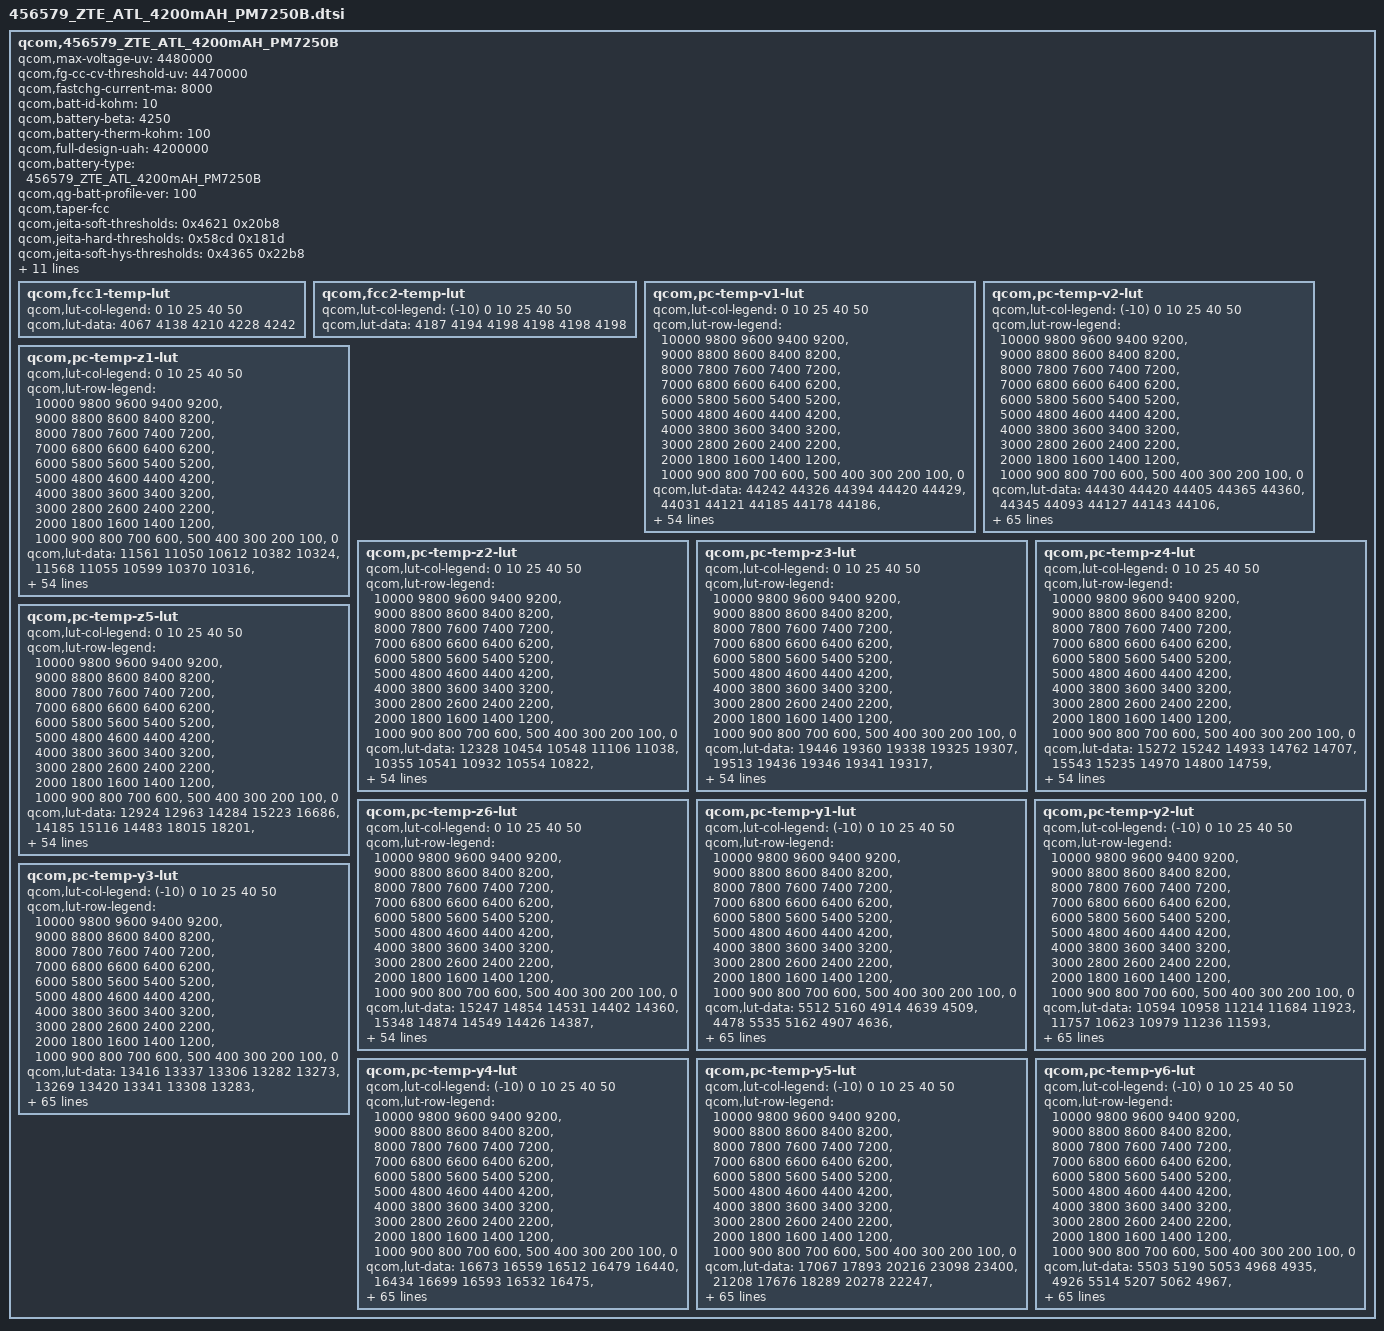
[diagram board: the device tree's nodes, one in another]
qcom,456579_ZTE_ATL_4200mAH_PM7250B {
	/* 456579_ZTE_ATL_4200mAH_PM7250B */
	qcom,max-voltage-uv = <4480000>;
	qcom,fg-cc-cv-threshold-uv = <4470000>;
	qcom,fastchg-current-ma = <8000>;
	qcom,batt-id-kohm = <10>;
	qcom,battery-beta = <4250>;
	qcom,battery-therm-kohm = <100>;
	qcom,full-design-uah = <4200000>;
	qcom,battery-type = "456579_ZTE_ATL_4200mAH_PM7250B";
	qcom,qg-batt-profile-ver = <100>;
	qcom,taper-fcc;
	qcom,jeita-soft-thresholds = <0x4621 0x20b8>;
	qcom,jeita-hard-thresholds = <0x58cd 0x181d>;
	qcom,jeita-soft-hys-thresholds = <0x4365 0x22b8>;
	qcom,jeita-soft-fcc-ua = <4200000 2100000>;
	qcom,jeita-soft-fv-uv = <4450000 4100000>;
	qcom,jeita-cool-step-chg-idx = <1>;
	qcom,jeita-cool-step-chg-fcc = <2100000>;
	qcom,jeita-cool-step-chg-fv = <4200000>;
	qcom,jeita-fcc-ranges = <0  49  800000
				50  149  4200000
				150 389  8000000
				390 409  6000000
				410 429  4800000
				430 449  3000000
				450 549  2000000>;

	qcom,jeita-fv-ranges = <0  49  4450000
				50  149  4450000
				150 389  4480000
				390 409  4480000
				410 429  4480000
				430 449  4480000
				450 549  4100000>;

	qcom,step-chg-ranges = <3400000  4200000  8000000
				4201000  4450000  6000000
				4451000  4480000  2940000>;

	qcom,fcc1-temp-lut {
		qcom,lut-col-legend = <0 10 25 40 50>;
		qcom,lut-data = <4067 4138 4210 4228 4242>;
	};

	qcom,fcc2-temp-lut {
		qcom,lut-col-legend = <(-10) 0 10 25 40 50>;
		qcom,lut-data = <4187 4194 4198 4198 4198 4198>;
	};

	qcom,pc-temp-v1-lut {
		qcom,lut-col-legend = <0 10 25 40 50>;
		qcom,lut-row-legend = <10000 9800 9600 9400 9200>,
			<9000 8800 8600 8400 8200>,
			<8000 7800 7600 7400 7200>,
			<7000 6800 6600 6400 6200>,
			<6000 5800 5600 5400 5200>,
			<5000 4800 4600 4400 4200>,
			<4000 3800 3600 3400 3200>,
			<3000 2800 2600 2400 2200>,
			<2000 1800 1600 1400 1200>,
			<1000 900 800 700 600>,
			<500 400 300 200 100>,
			<0>;

		qcom,lut-data = <44242 44326 44394 44420 44429>,
			<44031 44121 44185 44178 44186>,
			<43819 43915 43974 43968 43972>,
			<43606 43712 43761 43761 43767>,
			<43383 43504 43547 43555 43561>,
			<43149 43281 43328 43346 43355>,
			<42913 43044 43098 43122 43136>,
			<42675 42804 42860 42885 42903>,
			<42437 42564 42620 42646 42667>,
			<42203 42322 42375 42404 42426>,
			<41973 42084 42130 42162 42184>,
			<41746 41846 41891 41923 41944>,
			<41524 41616 41654 41685 41707>,
			<41305 41390 41423 41452 41474>,
			<41097 41172 41197 41225 41247>,
			<40904 40963 40978 41005 41027>,
			<40717 40763 40768 40792 40812>,
			<40522 40567 40564 40587 40604>,
			<40323 40384 40374 40391 40405>,
			<40126 40200 40200 40212 40223>,
			<39940 39985 40016 40029 40040>,
			<39754 39716 39783 39809 39824>,
			<39549 39468 39527 39565 39582>,
			<39298 39288 39317 39349 39364>,
			<39087 39136 39142 39156 39173>,
			<38975 39002 38989 38989 39005>,
			<38896 38883 38857 38856 38865>,
			<38816 38775 38740 38743 38746>,
			<38727 38675 38634 38637 38635>,
			<38639 38581 38537 38535 38531>,
			<38563 38498 38450 38441 38434>,
			<38493 38422 38372 38355 38346>,
			<38431 38355 38301 38276 38265>,
			<38375 38295 38236 38204 38189>,
			<38325 38243 38178 38142 38123>,
			<38282 38194 38124 38080 38055>,
			<38247 38155 38074 38015 37976>,
			<38205 38112 38026 37946 37889>,
			<38130 38044 37958 37866 37797>,
			<38024 37944 37864 37771 37701>,
			<37907 37830 37755 37663 37594>,
			<37772 37699 37631 37537 37465>,
			<37618 37551 37489 37395 37318>,
			<37435 37373 37317 37231 37151>,
			<37277 37218 37167 37097 37025>,
			<37204 37122 37077 37019 36957>,
			<37170 37100 37052 36998 36940>,
			<37143 37077 37037 36982 36925>,
			<37120 37056 37011 36961 36899>,
			<37032 36980 36917 36837 36740>,
			<36698 36658 36576 36487 36379>,
			<36206 36185 36098 36013 35900>,
			<35574 35567 35478 35398 35279>,
			<34701 34719 34631 34562 34429>,
			<33284 33361 33301 33262 33102>,
			<30000 30000 30000 30000 30000>;
	};

	qcom,pc-temp-v2-lut {
		qcom,lut-col-legend = <(-10) 0 10 25 40 50>;
		qcom,lut-row-legend = <10000 9800 9600 9400 9200>,
			<9000 8800 8600 8400 8200>,
			<8000 7800 7600 7400 7200>,
			<7000 6800 6600 6400 6200>,
			<6000 5800 5600 5400 5200>,
			<5000 4800 4600 4400 4200>,
			<4000 3800 3600 3400 3200>,
			<3000 2800 2600 2400 2200>,
			<2000 1800 1600 1400 1200>,
			<1000 900 800 700 600>,
			<500 400 300 200 100>,
			<0>;

		qcom,lut-data = <44430 44420 44405 44365 44360>,
			<44345 44093 44127 44143 44106>,
			<44102 44090 43788 43860 43898>,
			<43860 43857 43847 43522 43622>,
			<43672 43631 43629 43620 43291>,
			<43415 43467 43419 43418 43410>,
			<43063 43204 43257 43203 43204>,
			<43197 42826 42971 43026 42970>,
			<42974 42968 42585 42729 42786>,
			<42730 42737 42733 42338 42485>,
			<42545 42489 42499 42496 42083>,
			<42237 42301 42245 42257 42254>,
			<41828 41992 42059 42004 42017>,
			<42014 41567 41753 41820 41765>,
			<41779 41777 41317 41519 41584>,
			<41530 41544 41543 41128 41290>,
			<41352 41301 41315 41314 40994>,
			<41066 41123 41077 41091 41089>,
			<40840 40853 40902 40860 40874>,
			<40871 40584 40667 40690 40649>,
			<40663 40661 40262 40485 40484>,
			<40444 40458 40458 39977 40263>,
			<40285 40249 40263 40264 39713>,
			<39986 40096 40067 40083 40082>,
			<39466 39712 39889 39870 39889>,
			<39887 39236 39464 39623 39624>,
			<39652 39650 39022 39232 39340>,
			<39363 39402 39399 38823 39032>,
			<39120 39147 39188 39188 38631>,
			<38855 38941 38959 38998 39004>,
			<38471 38697 38785 38799 38835>,
			<38846 38349 38556 38646 38665>,
			<38703 38715 38249 38427 38521>,
			<38549 38588 38600 38172 38304>,
			<38407 38441 38481 38491 38110>,
			<38183 38302 38342 38382 38389>,
			<38055 38083 38206 38251 38290>,
			<38296 38002 38007 38119 38165>,
			<38206 38212 37951 37946 38040>,
			<38085 38128 38134 37896 37899>,
			<37964 38011 38052 38054 37841>,
			<37865 37892 37944 37981 37976>,
			<37782 37830 37829 37874 37901>,
			<37886 37719 37791 37780 37794>,
			<37798 37766 37651 37748 37735>,
			<37709 37681 37631 37574 37690>,
			<37671 37621 37575 37518 37484>,
			<37612 37586 37532 37478 37423>,
			<37381 37511 37485 37433 37376>,
			<37323 37255 37369 37361 37322>,
			<37264 37207 37114 37195 37218>,
			<37196 37140 37078 36976 37002>,
			<37046 37032 36978 36916 36864>,
			<36862 36921 36925 36887 36834>,
			<36783 36794 36862 36883 36856>,
			<36805 36747 36763 36833 36866>,
			<36841 36789 36708 36731 36809>,
			<36848 36822 36771 36650 36677>,
			<36758 36810 36787 36724 36521>,
			<36535 36634 36690 36639 36496>,
			<36213 36189 36277 36324 36249>,
			<36076 35706 35660 35737 35814>,
			<35733 35535 35011 34970 35045>,
			<35162 35071 34834 34042 34007>,
			<34086 34283 34174 33879 32581>,
			<32461 32614 32902 32854 32440>,
			<28493 28126 29188 28731 29235>,
			<28588>;
	};

	qcom,pc-temp-z1-lut {
		qcom,lut-col-legend = <0 10 25 40 50>;
		qcom,lut-row-legend = <10000 9800 9600 9400 9200>,
			<9000 8800 8600 8400 8200>,
			<8000 7800 7600 7400 7200>,
			<7000 6800 6600 6400 6200>,
			<6000 5800 5600 5400 5200>,
			<5000 4800 4600 4400 4200>,
			<4000 3800 3600 3400 3200>,
			<3000 2800 2600 2400 2200>,
			<2000 1800 1600 1400 1200>,
			<1000 900 800 700 600>,
			<500 400 300 200 100>,
			<0>;

		qcom,lut-data = <11561 11050 10612 10382 10324>,
			<11568 11055 10599 10370 10316>,
			<11566 11054 10587 10365 10312>,
			<11558 11042 10575 10361 10309>,
			<11545 11025 10564 10357 10307>,
			<11516 11012 10554 10353 10306>,
			<11488 11002 10544 10351 10304>,
			<11469 10990 10535 10348 10302>,
			<11453 10970 10529 10346 10300>,
			<11443 10952 10526 10343 10299>,
			<11432 10949 10524 10341 10299>,
			<11423 10951 10520 10339 10298>,
			<11420 10952 10517 10338 10297>,
			<11419 10946 10517 10338 10296>,
			<11416 10936 10518 10338 10297>,
			<11412 10932 10518 10338 10298>,
			<11405 10933 10518 10339 10299>,
			<11398 10934 10518 10340 10300>,
			<11379 10932 10518 10340 10301>,
			<11366 10927 10520 10341 10302>,
			<11366 10926 10523 10343 10302>,
			<11368 10926 10524 10343 10303>,
			<11372 10928 10526 10344 10304>,
			<11382 10936 10528 10345 10306>,
			<11391 10950 10533 10347 10308>,
			<11391 10956 10538 10349 10311>,
			<11389 10956 10543 10352 10313>,
			<11389 10955 10548 10354 10315>,
			<11402 10955 10552 10357 10316>,
			<11418 10955 10557 10359 10317>,
			<11423 10956 10562 10362 10318>,
			<11426 10957 10566 10364 10320>,
			<11428 10960 10570 10366 10322>,
			<11425 10966 10575 10369 10323>,
			<11422 10977 10582 10372 10325>,
			<11419 10985 10589 10376 10327>,
			<11410 10988 10593 10379 10329>,
			<11403 10991 10596 10383 10331>,
			<11417 10993 10600 10386 10334>,
			<11446 10997 10605 10387 10336>,
			<11454 11004 10611 10389 10338>,
			<11443 11074 10618 10392 10339>,
			<11440 11121 10626 10394 10340>,
			<11473 11041 10633 10395 10342>,
			<11492 11032 10637 10397 10342>,
			<11484 11040 10642 10398 10343>,
			<11471 11026 10641 10398 10341>,
			<11461 11037 10649 10399 10343>,
			<11482 11047 10652 10401 10345>,
			<11476 11034 10661 10405 10345>,
			<11496 11040 10662 10408 10349>,
			<11486 11054 10672 10411 10352>,
			<11492 11070 10679 10415 10355>,
			<11519 11095 10688 10424 10362>,
			<11519 11095 10688 10424 10362>,
			<11519 11095 10688 10424 10362>;
	};

	qcom,pc-temp-z2-lut {
		qcom,lut-col-legend = <0 10 25 40 50>;
		qcom,lut-row-legend = <10000 9800 9600 9400 9200>,
			<9000 8800 8600 8400 8200>,
			<8000 7800 7600 7400 7200>,
			<7000 6800 6600 6400 6200>,
			<6000 5800 5600 5400 5200>,
			<5000 4800 4600 4400 4200>,
			<4000 3800 3600 3400 3200>,
			<3000 2800 2600 2400 2200>,
			<2000 1800 1600 1400 1200>,
			<1000 900 800 700 600>,
			<500 400 300 200 100>,
			<0>;

		qcom,lut-data = <12328 10454 10548 11106 11038>,
			<10355 10541 10932 10554 10822>,
			<10358 10573 11638 10816 10937>,
			<10375 10562 11792 10941 11004>,
			<10375 10543 11209 10859 10926>,
			<10346 10513 10705 10756 10804>,
			<10313 10458 10815 10738 10781>,
			<10290 10432 11087 10747 10786>,
			<10270 10439 11138 10752 10795>,
			<10265 10451 10873 10733 10815>,
			<10268 10456 10654 10712 10840>,
			<10274 10460 10782 10715 10853>,
			<10284 10464 11065 10721 10863>,
			<10305 10473 11183 10726 10874>,
			<10323 10485 11214 10737 10889>,
			<10337 10496 11243 10753 10906>,
			<10349 10505 11292 10775 10923>,
			<10357 10515 11350 10806 10943>,
			<10363 10525 11403 10835 10959>,
			<10368 10534 11461 10861 10969>,
			<10375 10538 11494 10889 10981>,
			<10382 10539 11295 10935 11023>,
			<10380 10540 10921 10993 11110>,
			<10351 10541 10852 11009 11138>,
			<10325 10542 10919 10982 10985>,
			<10332 10547 10963 10937 10809>,
			<10356 10572 10905 10836 10765>,
			<10378 10592 10787 10681 10744>,
			<10397 10578 10728 10635 10739>,
			<10413 10545 10697 10642 10747>,
			<10421 10534 10683 10653 10763>,
			<10427 10545 10698 10677 10804>,
			<10433 10561 10731 10720 10885>,
			<10442 10577 10764 10777 10960>,
			<10451 10596 10810 10868 11034>,
			<10453 10608 10853 10951 11102>,
			<10454 10612 10884 10999 11171>,
			<10454 10617 10912 11036 11245>,
			<10464 10629 10941 11061 11265>,
			<10482 10652 10975 11087 11262>,
			<10485 10662 10993 11101 11256>,
			<10461 10639 10981 11088 11218>,
			<10450 10622 10963 11070 11157>,
			<10470 10641 10954 11014 11095>,
			<10618 10729 10933 11020 11086>,
			<10498 10764 10939 11096 11122>,
			<10580 10727 10882 11080 11106>,
			<11069 10714 10881 11077 11205>,
			<13696 10752 10859 11199 11350>,
			<13300 10809 10942 11046 10987>,
			<10829 10929 10857 10818 10855>,
			<10598 11126 10779 10764 10774>,
			<10226 11060 10703 10694 10723>,
			<10025 10984 10652 10648 10661>,
			<10025 10984 10652 10648 10661>,
			<10025 10984 10652 10648 10661>;
	};

	qcom,pc-temp-z3-lut {
		qcom,lut-col-legend = <0 10 25 40 50>;
		qcom,lut-row-legend = <10000 9800 9600 9400 9200>,
			<9000 8800 8600 8400 8200>,
			<8000 7800 7600 7400 7200>,
			<7000 6800 6600 6400 6200>,
			<6000 5800 5600 5400 5200>,
			<5000 4800 4600 4400 4200>,
			<4000 3800 3600 3400 3200>,
			<3000 2800 2600 2400 2200>,
			<2000 1800 1600 1400 1200>,
			<1000 900 800 700 600>,
			<500 400 300 200 100>,
			<0>;

		qcom,lut-data = <19446 19360 19338 19325 19307>,
			<19513 19436 19346 19341 19317>,
			<19555 19477 19379 19348 19331>,
			<19598 19495 19399 19353 19339>,
			<19622 19505 19410 19356 19338>,
			<19636 19512 19418 19358 19336>,
			<19644 19519 19423 19357 19334>,
			<19645 19521 19426 19354 19332>,
			<19643 19514 19422 19351 19330>,
			<19641 19502 19404 19346 19328>,
			<19635 19496 19389 19340 19326>,
			<19627 19492 19391 19338 19325>,
			<19620 19489 19398 19336 19323>,
			<19612 19483 19399 19334 19320>,
			<19604 19478 19396 19331 19317>,
			<19598 19476 19393 19328 19313>,
			<19593 19476 19390 19325 19311>,
			<19588 19476 19387 19323 19310>,
			<19580 19472 19384 19320 19309>,
			<19576 19466 19380 19317 19307>,
			<19585 19467 19376 19315 19305>,
			<19601 19481 19374 19317 19307>,
			<19605 19492 19374 19323 19316>,
			<19602 19479 19374 19332 19325>,
			<19597 19453 19375 19352 19334>,
			<19593 19448 19376 19368 19341>,
			<19586 19472 19388 19364 19340>,
			<19584 19493 19408 19353 19338>,
			<19590 19493 19412 19346 19335>,
			<19596 19492 19407 19342 19331>,
			<19596 19490 19399 19339 19327>,
			<19592 19484 19392 19335 19323>,
			<19588 19478 19385 19331 19319>,
			<19585 19473 19380 19327 19314>,
			<19581 19469 19377 19323 19308>,
			<19578 19466 19374 19320 19304>,
			<19575 19464 19372 19321 19305>,
			<19572 19463 19371 19322 19307>,
			<19566 19459 19370 19324 19309>,
			<19558 19452 19368 19326 19313>,
			<19552 19446 19366 19327 19317>,
			<19547 19443 19363 19329 19317>,
			<19541 19439 19360 19330 19318>,
			<19530 19432 19358 19329 19320>,
			<19493 19413 19349 19323 19318>,
			<19361 19405 19340 19313 19307>,
			<19360 19397 19341 19312 19302>,
			<19347 19398 19332 19310 19297>,
			<19259 19381 19333 19300 19292>,
			<19259 19366 19331 19319 19310>,
			<19260 19360 19341 19325 19313>,
			<19261 19316 19348 19326 19314>,
			<19263 19318 19353 19329 19316>,
			<19264 19319 19360 19331 19318>,
			<19264 19319 19360 19331 19318>,
			<19264 19319 19360 19331 19318>;
	};

	qcom,pc-temp-z4-lut {
		qcom,lut-col-legend = <0 10 25 40 50>;
		qcom,lut-row-legend = <10000 9800 9600 9400 9200>,
			<9000 8800 8600 8400 8200>,
			<8000 7800 7600 7400 7200>,
			<7000 6800 6600 6400 6200>,
			<6000 5800 5600 5400 5200>,
			<5000 4800 4600 4400 4200>,
			<4000 3800 3600 3400 3200>,
			<3000 2800 2600 2400 2200>,
			<2000 1800 1600 1400 1200>,
			<1000 900 800 700 600>,
			<500 400 300 200 100>,
			<0>;

		qcom,lut-data = <15272 15242 14933 14762 14707>,
			<15543 15235 14970 14800 14759>,
			<15483 15215 14924 14789 14748>,
			<15356 15136 14883 14776 14735>,
			<15247 15028 14845 14752 14716>,
			<15147 14957 14807 14726 14697>,
			<15061 14900 14766 14711 14689>,
			<14995 14855 14726 14702 14685>,
			<14941 14817 14714 14695 14682>,
			<14896 14788 14722 14692 14677>,
			<14855 14775 14729 14689 14672>,
			<14825 14767 14717 14684 14667>,
			<14811 14761 14693 14678 14663>,
			<14802 14757 14680 14672 14659>,
			<14796 14753 14673 14667 14656>,
			<14790 14748 14668 14662 14652>,
			<14787 14741 14664 14657 14647>,
			<14791 14737 14661 14652 14642>,
			<14814 14738 14659 14648 14637>,
			<14830 14740 14659 14646 14633>,
			<14822 14749 14658 14644 14631>,
			<14807 14788 14692 14662 14642>,
			<14810 14831 14759 14707 14678>,
			<14875 14861 14786 14722 14694>,
			<14933 14886 14795 14711 14689>,
			<14927 14888 14799 14698 14682>,
			<14900 14848 14779 14693 14675>,
			<14877 14806 14741 14690 14668>,
			<14857 14791 14726 14686 14662>,
			<14842 14781 14720 14679 14657>,
			<14838 14779 14717 14672 14653>,
			<14835 14778 14715 14668 14649>,
			<14834 14779 14713 14664 14646>,
			<14834 14779 14713 14663 14644>,
			<14834 14780 14714 14662 14644>,
			<14833 14780 14716 14661 14645>,
			<14827 14777 14719 14667 14652>,
			<14820 14773 14723 14676 14665>,
			<14814 14770 14725 14679 14668>,
			<14807 14768 14726 14679 14663>,
			<14797 14764 14727 14678 14657>,
			<14777 14748 14718 14674 14654>,
			<14755 14728 14704 14667 14652>,
			<14734 14714 14696 14665 14650>,
			<14694 14684 14681 14658 14644>,
			<14791 14663 14663 14648 14634>,
			<14784 14658 14651 14638 14629>,
			<14793 14649 14643 14627 14620>,
			<14881 14657 14634 14624 14616>,
			<14874 14674 14645 14621 14619>,
			<14884 14692 14645 14623 14621>,
			<14886 14741 14639 14623 14621>,
			<14885 14740 14633 14621 14621>,
			<14891 14742 14627 14621 14621>,
			<14891 14742 14627 14621 14621>,
			<14891 14742 14627 14621 14621>;
	};

	qcom,pc-temp-z5-lut {
		qcom,lut-col-legend = <0 10 25 40 50>;
		qcom,lut-row-legend = <10000 9800 9600 9400 9200>,
			<9000 8800 8600 8400 8200>,
			<8000 7800 7600 7400 7200>,
			<7000 6800 6600 6400 6200>,
			<6000 5800 5600 5400 5200>,
			<5000 4800 4600 4400 4200>,
			<4000 3800 3600 3400 3200>,
			<3000 2800 2600 2400 2200>,
			<2000 1800 1600 1400 1200>,
			<1000 900 800 700 600>,
			<500 400 300 200 100>,
			<0>;

		qcom,lut-data = <12924 12963 14284 15223 16686>,
			<14185 15116 14483 18015 18201>,
			<15175 16557 16045 18962 20616>,
			<16381 17347 17301 19673 22185>,
			<17484 17997 18261 20314 22767>,
			<18430 18858 19282 20877 23130>,
			<19383 19919 21222 21507 23216>,
			<20405 20965 23753 22172 23092>,
			<21450 21970 24181 22391 23032>,
			<22560 22905 21882 21768 23227>,
			<23975 23657 19975 21077 23548>,
			<25421 24321 21370 21201 23871>,
			<26640 24777 24697 21787 24256>,
			<27800 25026 26920 22219 24419>,
			<28320 25270 28419 22461 23985>,
			<28412 25896 29527 22595 23432>,
			<28438 27793 30386 22719 23729>,
			<28351 29056 31231 23111 25204>,
			<27729 28093 31768 23562 26535>,
			<27293 26386 32142 24230 27769>,
			<29413 27031 32377 24675 28701>,
			<33478 34820 31137 24189 28173>,
			<34903 40978 28105 23072 26013>,
			<34099 35409 25323 22527 24187>,
			<32834 24026 20787 22593 22684>,
			<31228 20814 17823 22683 21681>,
			<28966 23266 19676 22232 21997>,
			<28265 26548 23644 21415 23275>,
			<30687 29346 26118 21251 24597>,
			<34079 32165 27637 22285 25968>,
			<36159 34178 28908 23705 27269>,
			<37847 35750 30041 24951 28339>,
			<38839 36766 31110 26249 29298>,
			<39298 37050 32425 27461 29712>,
			<39588 37224 34255 28795 29344>,
			<39562 37339 35296 29561 28917>,
			<39147 37235 34997 29474 28188>,
			<38723 36910 34182 29220 26647>,
			<38440 35930 32820 28907 26429>,
			<38105 33716 29805 28257 28732>,
			<37714 32413 27489 27820 31319>,
			<36865 32135 26905 29018 32773>,
			<36430 31870 26428 30512 33827>,
			<36409 30491 25303 28799 34510>,
			<36387 31602 24388 25094 31721>,
			<21824 34211 24645 22460 24819>,
			<21183 29814 27755 25216 25276>,
			<19615 31621 25826 30312 28450>,
			<11472 23100 29930 26531 29047>,
			<11527 18999 22864 36551 40961>,
			<11582 18078 22651 35283 38084>,
			<11508 13405 24417 34104 37226>,
			<11464 13307 26887 35247 35632>,
			<11410 13316 31486 35142 35266>,
			<11410 13316 31486 35142 35266>,
			<11410 13316 31486 35142 35266>;
	};

	qcom,pc-temp-z6-lut {
		qcom,lut-col-legend = <0 10 25 40 50>;
		qcom,lut-row-legend = <10000 9800 9600 9400 9200>,
			<9000 8800 8600 8400 8200>,
			<8000 7800 7600 7400 7200>,
			<7000 6800 6600 6400 6200>,
			<6000 5800 5600 5400 5200>,
			<5000 4800 4600 4400 4200>,
			<4000 3800 3600 3400 3200>,
			<3000 2800 2600 2400 2200>,
			<2000 1800 1600 1400 1200>,
			<1000 900 800 700 600>,
			<500 400 300 200 100>,
			<0>;

		qcom,lut-data = <15247 14854 14531 14402 14360>,
			<15348 14874 14549 14426 14387>,
			<15317 14876 14544 14425 14388>,
			<15251 14842 14536 14423 14389>,
			<15190 14788 14523 14415 14382>,
			<15127 14751 14506 14403 14371>,
			<15068 14721 14491 14396 14366>,
			<15021 14693 14475 14390 14363>,
			<14978 14666 14464 14384 14360>,
			<14941 14643 14457 14380 14357>,
			<14907 14631 14451 14375 14353>,
			<14880 14624 14445 14371 14350>,
			<14864 14617 14439 14368 14347>,
			<14853 14611 14434 14364 14344>,
			<14845 14606 14430 14360 14340>,
			<14838 14602 14426 14356 14337>,
			<14833 14599 14422 14352 14334>,
			<14833 14596 14420 14349 14331>,
			<14837 14594 14417 14346 14328>,
			<14840 14592 14415 14343 14325>,
			<14841 14595 14413 14341 14323>,
			<14842 14622 14427 14350 14329>,
			<14848 14646 14455 14372 14350>,
			<14876 14649 14468 14385 14362>,
			<14900 14651 14474 14392 14365>,
			<14896 14651 14477 14395 14367>,
			<14883 14647 14475 14393 14366>,
			<14875 14641 14471 14386 14361>,
			<14872 14638 14467 14380 14356>,
			<14871 14634 14463 14375 14353>,
			<14869 14632 14459 14371 14349>,
			<14867 14630 14455 14367 14345>,
			<14866 14629 14451 14363 14341>,
			<14866 14628 14450 14361 14338>,
			<14867 14628 14449 14358 14335>,
			<14867 14628 14449 14357 14333>,
			<14867 14628 14450 14359 14336>,
			<14867 14629 14452 14365 14343>,
			<14867 14629 14454 14367 14346>,
			<14867 14628 14455 14369 14346>,
			<14867 14628 14455 14370 14346>,
			<14864 14623 14451 14368 14345>,
			<14861 14617 14445 14366 14344>,
			<14857 14613 14442 14365 14345>,
			<14834 14598 14433 14360 14342>,
			<14818 14588 14422 14350 14332>,
			<14816 14583 14418 14345 14327>,
			<14814 14580 14410 14339 14320>,
			<14813 14578 14408 14333 14315>,
			<14817 14582 14413 14342 14327>,
			<14828 14592 14420 14348 14331>,
			<14837 14595 14423 14349 14332>,
			<14846 14601 14426 14351 14334>,
			<14865 14611 14430 14354 14337>,
			<14865 14611 14430 14354 14337>,
			<14865 14611 14430 14354 14337>;
	};

	qcom,pc-temp-y1-lut {
		qcom,lut-col-legend = <(-10) 0 10 25 40 50>;
		qcom,lut-row-legend = <10000 9800 9600 9400 9200>,
			<9000 8800 8600 8400 8200>,
			<8000 7800 7600 7400 7200>,
			<7000 6800 6600 6400 6200>,
			<6000 5800 5600 5400 5200>,
			<5000 4800 4600 4400 4200>,
			<4000 3800 3600 3400 3200>,
			<3000 2800 2600 2400 2200>,
			<2000 1800 1600 1400 1200>,
			<1000 900 800 700 600>,
			<500 400 300 200 100>,
			<0>;

		qcom,lut-data = <5512 5160 4914 4639 4509>,
			<4478 5535 5162 4907 4636>,
			<4508 4477 5552 5162 4899>,
			<4633 4506 4476 5564 5161>,
			<4892 4629 4504 4475 5570>,
			<5159 4886 4625 4503 4474>,
			<5572 5157 4881 4622 4502>,
			<4474 5566 5154 4876 4618>,
			<4501 4473 5556 5148 4872>,
			<4614 4501 4472 5553 5143>,
			<4871 4611 4500 4472 5553>,
			<5134 4870 4608 4499 4472>,
			<5552 5129 4869 4605 4498>,
			<4472 5552 5130 4866 4603>,
			<4497 4472 5555 5132 4860>,
			<4601 4495 4471 5563 5130>,
			<4855 4600 4495 4470 5584>,
			<5126 4848 4600 4494 4469>,
			<5598 5124 4844 4599 4494>,
			<4469 5595 5127 4843 4599>,
			<4494 4470 5588 5132 4843>,
			<4598 4494 4472 5580 5134>,
			<4845 4598 4494 4473 5571>,
			<5135 4847 4601 4494 4472>,
			<5565 5136 4850 4603 4494>,
			<4472 5572 5135 4850 4604>,
			<4495 4472 5584 5133 4851>,
			<4605 4496 4472 5589 5134>,
			<4852 4607 4497 4473 5584>,
			<5140 4853 4610 4499 4473>,
			<5580 5144 4855 4614 4500>,
			<4474 5581 5145 4859 4615>,
			<4501 4474 5582 5145 4864>,
			<4617 4501 4475 5578 5147>,
			<4865 4619 4502 4475 5566>,
			<5151 4863 4623 4503 4477>,
			<5557 5155 4863 4628 4505>,
			<4478 5571 5158 4868 4633>,
			<4507 4479 5597 5162 4877>,
			<4638 4508 4480 5604 5166>,
			<4881 4642 4510 4481 5594>,
			<5170 4883 4645 4511 4482>,
			<5586 5174 4884 4648 4513>,
			<4484 5583 5174 4888 4653>,
			<4515 4485 5579 5170 4894>,
			<4657 4517 4485 5580 5169>,
			<4897 4660 4519 4486 5583>,
			<5166 4899 4661 4520 4488>,
			<5585 5165 4901 4663 4521>,
			<4489 5584 5176 4911 4666>,
			<4523 4490 5583 5188 4921>,
			<4670 4524 4491 5580 5187>,
			<4926 4671 4525 4492 5593>,
			<5181 4932 4676 4527 4493>,
			<5616 5184 4928 4682 4528>,
			<4495 5602 5180 4934 4685>,
			<4531 4494 5594 5183 4937>,
			<4687 4529 4497 5609 5193>,
			<4939 4688 4531 4494 5619>,
			<5178 4944 4689 4531 4495>,
			<5651 5183 4953 4697 4532>,
			<4496 5722 5218 4959 4699>,
			<4533 4498 5823 5241 4969>,
			<4709 4537 4501 5864 5293>,
			<4972 4720 4541 4505 5864>,
			<5293 4972 4720 4541 4505>,
			<5864 5293 4972 4720 4541>,
			<4505>;
	};

	qcom,pc-temp-y2-lut {
		qcom,lut-col-legend = <(-10) 0 10 25 40 50>;
		qcom,lut-row-legend = <10000 9800 9600 9400 9200>,
			<9000 8800 8600 8400 8200>,
			<8000 7800 7600 7400 7200>,
			<7000 6800 6600 6400 6200>,
			<6000 5800 5600 5400 5200>,
			<5000 4800 4600 4400 4200>,
			<4000 3800 3600 3400 3200>,
			<3000 2800 2600 2400 2200>,
			<2000 1800 1600 1400 1200>,
			<1000 900 800 700 600>,
			<500 400 300 200 100>,
			<0>;

		qcom,lut-data = <10594 10958 11214 11684 11923>,
			<11757 10623 10979 11236 11593>,
			<11784 11749 10666 10990 11239>,
			<11503 11651 11729 10711 10992>,
			<11228 11419 11534 11700 10746>,
			<10988 11206 11347 11444 11663>,
			<10761 10980 11178 11292 11391>,
			<11621 10758 10965 11130 11248>,
			<11378 11563 10752 10942 11077>,
			<11215 11382 11504 10746 10924>,
			<11055 11200 11377 11480 10735>,
			<10906 11041 11191 11355 11469>,
			<10729 10897 11034 11184 11332>,
			<11456 10757 10910 11034 11185>,
			<11312 11417 10813 10938 11035>,
			<11193 11295 11364 10852 10966>,
			<11042 11202 11291 11335 10882>,
			<10998 11080 11214 11296 11314>,
			<10908 11030 11130 11231 11304>,
			<11305 10941 11066 11182 11263>,
			<11332 11345 10976 11104 11245>,
			<11316 11380 11413 10981 11133>,
			<11321 11405 11427 11432 10959>,
			<11164 11424 11581 11486 11423>,
			<10936 11180 11478 11682 11544>,
			<11422 10922 11166 11439 11665>,
			<11601 11557 10906 11140 11376>,
			<11627 11652 11768 10887 11129>,
			<11352 11581 11671 11824 10864>,
			<11129 11340 11505 11666 11799>,
			<10826 11130 11335 11462 11664>,
			<11786 10523 11133 11337 11490>,
			<11677 11842 10016 11135 11343>,
			<11541 11699 11918 9838 11131>,
			<11353 11573 11735 11947 9793>,
			<11119 11380 11612 11805 11957>,
			<9763 11111 11399 11640 11869>,
			<11970 9740 11119 11402 11659>,
			<11913 12031 9723 11133 11397>,
			<11688 11950 12109 9709 11127>,
			<11388 11714 11968 12118 9698>,
			<11081 11368 11742 11985 12086>,
			<9689 11031 11352 11751 11987>,
			<12063 9684 10999 11344 11697>,
			<11944 12047 9680 10966 11335>,
			<11620 11888 12021 9677 10919>,
			<11314 11606 11873 12005 9674>,
			<10852 11260 11619 11875 11978>,
			<9672 10744 11191 11626 11874>,
			<11946 9670 10346 11114 11570>,
			<11808 11867 9669 9900 11022>,
			<11497 11746 11803 9667 9769>,
			<10916 11472 11803 11864 9665>,
			<9713 10803 11404 11781 11824>,
			<9664 9696 10795 11373 11631>,
			<11693 9663 9688 10702 11359>,
			<11515 11551 9661 9681 10721>,
			<11336 11454 11444 9660 9676>,
			<10642 11381 11372 11488 9657>,
			<9670 10607 11316 11423 11453>,
			<9654 9666 10497 11286 11356>,
			<11489 9650 9661 10026 11193>,
			<11349 11434 9649 9655 9829>,
			<11168 11305 11276 9648 9650>,
			<9699 11131 11191 11178 9648>,
			<9650 9699 11131 11191 11178>,
			<9648 9650 9699 11131 11191>,
			<11178>;
	};

	qcom,pc-temp-y3-lut {
		qcom,lut-col-legend = <(-10) 0 10 25 40 50>;
		qcom,lut-row-legend = <10000 9800 9600 9400 9200>,
			<9000 8800 8600 8400 8200>,
			<8000 7800 7600 7400 7200>,
			<7000 6800 6600 6400 6200>,
			<6000 5800 5600 5400 5200>,
			<5000 4800 4600 4400 4200>,
			<4000 3800 3600 3400 3200>,
			<3000 2800 2600 2400 2200>,
			<2000 1800 1600 1400 1200>,
			<1000 900 800 700 600>,
			<500 400 300 200 100>,
			<0>;

		qcom,lut-data = <13416 13337 13306 13282 13273>,
			<13269 13420 13341 13308 13283>,
			<13272 13268 13423 13347 13311>,
			<13284 13272 13268 13427 13352>,
			<13313 13284 13272 13269 13431>,
			<13356 13315 13284 13272 13269>,
			<13434 13359 13316 13284 13272>,
			<13269 13438 13360 13317 13284>,
			<13273 13270 13442 13361 13317>,
			<13284 13274 13270 13442 13363>,
			<13318 13284 13275 13271 13438>,
			<13364 13320 13285 13275 13272>,
			<13433 13365 13321 13286 13276>,
			<13272 13431 13366 13322 13287>,
			<13276 13273 13428 13367 13323>,
			<13287 13277 13274 13424 13367>,
			<13323 13289 13278 13274 13412>,
			<13361 13323 13292 13281 13274>,
			<13405 13355 13322 13294 13282>,
			<13275 13407 13351 13319 13294>,
			<13282 13276 13411 13347 13314>,
			<13294 13282 13278 13410 13345>,
			<13314 13294 13282 13278 13398>,
			<13345 13317 13293 13282 13278>,
			<13386 13344 13319 13292 13282>,
			<13276 13380 13340 13315 13290>,
			<13281 13275 13375 13335 13309>,
			<13287 13278 13273 13370 13331>,
			<13305 13284 13276 13272 13362>,
			<13329 13303 13281 13273 13269>,
			<13357 13327 13302 13280 13271>,
			<13268 13351 13325 13301 13280>,
			<13271 13269 13344 13324 13300>,
			<13279 13271 13269 13345 13321>,
			<13300 13279 13271 13269 13351>,
			<13318 13300 13280 13272 13269>,
			<13359 13315 13299 13281 13272>,
			<13269 13368 13312 13299 13280>,
			<13271 13270 13381 13308 13299>,
			<13280 13271 13270 13394 13309>,
			<13299 13280 13271 13270 13409>,
			<13316 13298 13280 13272 13270>,
			<13426 13323 13298 13280 13272>,
			<13269 13450 13326 13298 13280>,
			<13272 13269 13479 13329 13300>,
			<13279 13271 13268 13511 13332>,
			<13300 13279 13270 13268 13545>,
			<13336 13301 13278 13270 13268>,
			<13583 13340 13301 13277 13269>,
			<13269 13627 13344 13302 13278>,
			<13270 13269 13678 13350 13304>,
			<13278 13271 13270 13734 13363>,
			<13307 13279 13270 13268 13813>,
			<13385 13310 13280 13270 13269>,
			<13895 13407 13311 13280 13273>,
			<13272 13960 13426 13313 13282>,
			<13273 13273 14053 13460 13319>,
			<13288 13277 13274 14186 13502>,
			<13325 13292 13278 13274 14393>,
			<13563 13334 13293 13277 13272>,
			<14924 13654 13337 13290 13275>,
			<13272 16533 13846 13346 13292>,
			<13276 13273 20473 14391 13379>,
			<13296 13278 13275 30877 16445>,
			<13480 13302 13281 13277 30877>,
			<16445 13480 13302 13281 13277>,
			<30877 16445 13480 13302 13281>,
			<13277>;
	};

	qcom,pc-temp-y4-lut {
		qcom,lut-col-legend = <(-10) 0 10 25 40 50>;
		qcom,lut-row-legend = <10000 9800 9600 9400 9200>,
			<9000 8800 8600 8400 8200>,
			<8000 7800 7600 7400 7200>,
			<7000 6800 6600 6400 6200>,
			<6000 5800 5600 5400 5200>,
			<5000 4800 4600 4400 4200>,
			<4000 3800 3600 3400 3200>,
			<3000 2800 2600 2400 2200>,
			<2000 1800 1600 1400 1200>,
			<1000 900 800 700 600>,
			<500 400 300 200 100>,
			<0>;

		qcom,lut-data = <16673 16559 16512 16479 16440>,
			<16434 16699 16593 16532 16475>,
			<16440 16433 16756 16638 16550>,
			<16473 16439 16432 16823 16683>,
			<16566 16471 16439 16432 16880>,
			<16717 16577 16469 16438 16431>,
			<16904 16731 16581 16469 16438>,
			<16430 16904 16727 16577 16470>,
			<16437 16429 16903 16719 16571>,
			<16471 16436 16429 16903 16712>,
			<16566 16472 16436 16429 16902>,
			<16705 16563 16473 16437 16429>,
			<16903 16702 16562 16475 16439>,
			<16430 16908 16705 16563 16478>,
			<16441 16431 16920 16714 16568>,
			<16482 16444 16433 16957 16728>,
			<16574 16486 16446 16436 17084>,
			<16761 16585 16489 16448 16439>,
			<17170 16801 16602 16494 16450>,
			<16442 17103 16857 16641 16504>,
			<16455 16445 16969 16912 16687>,
			<16519 16463 16447 16884 16909>,
			<16706 16541 16476 16454 16827>,
			<16828 16714 16578 16496 16471>,
			<16778 16744 16718 16598 16508>,
			<16481 16730 16690 16668 16574>,
			<16501 16476 16686 16646 16583>,
			<16530 16487 16464 16643 16614>,
			<16545 16500 16472 16454 16595>,
			<16591 16525 16476 16453 16441>,
			<16569 16573 16514 16465 16442>,
			<16435 16583 16560 16510 16466>,
			<16443 16435 16610 16548 16507>,
			<16467 16444 16435 16623 16533>,
			<16506 16470 16446 16436 16629>,
			<16511 16506 16475 16450 16440>,
			<16634 16500 16506 16481 16455>,
			<16444 16638 16504 16507 16487>,
			<16462 16450 16644 16513 16509>,
			<16493 16471 16457 16650 16521>,
			<16507 16498 16477 16461 16659>,
			<16530 16501 16503 16483 16465>,
			<16668 16541 16497 16506 16485>,
			<16467 16675 16562 16503 16497>,
			<16475 16458 16682 16588 16514>,
			<16480 16456 16444 16686 16603>,
			<16518 16469 16448 16440 16691>,
			<16614 16520 16460 16445 16439>,
			<16693 16619 16521 16456 16442>,
			<16438 16681 16612 16525 16459>,
			<16440 16436 16663 16601 16530>,
			<16463 16438 16434 16659 16592>,
			<16535 16461 16432 16426 16659>,
			<16590 16539 16464 16431 16424>,
			<16656 16587 16530 16467 16434>,
			<16425 16661 16598 16539 16475>,
			<16441 16432 16681 16617 16556>,
			<16480 16445 16452 16715 16647>,
			<16579 16492 16478 16499 16734>,
			<16673 16603 16515 16485 16456>,
			<16770 16665 16589 16482 16437>,
			<16432 17025 16680 16608 16492>,
			<16440 16437 18128 16757 16646>,
			<16517 16455 16454 24702 17698>,
			<16716 16566 16496 16510 24702>,
			<17698 16716 16566 16496 16510>,
			<24702 17698 16716 16566 16496>,
			<16510>;
	};

	qcom,pc-temp-y5-lut {
		qcom,lut-col-legend = <(-10) 0 10 25 40 50>;
		qcom,lut-row-legend = <10000 9800 9600 9400 9200>,
			<9000 8800 8600 8400 8200>,
			<8000 7800 7600 7400 7200>,
			<7000 6800 6600 6400 6200>,
			<6000 5800 5600 5400 5200>,
			<5000 4800 4600 4400 4200>,
			<4000 3800 3600 3400 3200>,
			<3000 2800 2600 2400 2200>,
			<2000 1800 1600 1400 1200>,
			<1000 900 800 700 600>,
			<500 400 300 200 100>,
			<0>;

		qcom,lut-data = <17067 17893 20216 23098 23400>,
			<21208 17676 18289 20278 22247>,
			<22471 21169 18259 18789 20234>,
			<21389 21328 21180 18799 19284>,
			<20107 20524 20214 21232 19280>,
			<19663 19921 19652 19367 21313>,
			<19685 19817 19697 18775 19030>,
			<21408 20074 19778 19386 17754>,
			<19191 21569 20378 19684 19030>,
			<16816 19444 21736 20269 19546>,
			<18786 16406 19450 21746 19258>,
			<19271 18622 16206 19169 21614>,
			<18169 18908 18415 16020 18786>,
			<21411 17232 18441 18043 15737>,
			<18179 20961 16394 17822 17526>,
			<15483 17545 20247 16381 16966>,
			<16913 15502 17626 19487 17446>,
			<15600 16113 15840 18682 18528>,
			<18854 14833 15409 16062 19377>,
			<18024 21417 15709 14839 15633>,
			<18576 18499 24486 17548 14406>,
			<14944 17131 19253 24950 19266>,
			<14996 14812 16329 19032 23908>,
			<21165 18682 15018 15787 17031>,
			<23165 22520 21689 15402 15548>,
			<15704 23364 23146 22700 18000>,
			<17778 17604 23738 23561 23326>,
			<21667 21309 20615 23645 23836>,
			<23403 22200 21833 21148 21932>,
			<24152 23325 21264 20783 20789>,
			<20168 24328 23253 20447 19887>,
			<20553 17491 24423 23068 20058>,
			<19471 20593 13786 24603 22849>,
			<19767 19136 20657 12877 24464>,
			<22907 19767 19033 20451 12901>,
			<22773 23052 20030 18733 19242>,
			<12977 21451 23277 20259 18406>,
			<18327 13158 19386 24083 20223>,
			<17850 18141 13475 16262 25097>,
			<20115 17187 18034 13652 16034>,
			<25168 20264 17246 18108 13811>,
			<18340 24505 20784 18304 18635>,
			<13991 20309 23935 21406 19360>,
			<19155 14334 20892 23590 22183>,
			<20091 19440 14812 21291 23141>,
			<22911 20657 19679 14996 21701>,
			<22479 22770 20565 19968 15041>,
			<22326 20906 21212 19585 20595>,
			<15032 22696 19698 19693 18944>,
			<21471 14854 20739 19168 18688>,
			<19591 23154 14465 17496 18837>,
			<18146 20626 25187 13542 15244>,
			<18892 19266 21925 27179 13166>,
			<14664 18921 19117 21624 26099>,
			<13233 14763 19747 18295 20381>,
			<24230 13492 14398 18075 17128>,
			<18331 25156 13643 14525 18320>,
			<18994 22305 25223 13731 14417>,
			<17441 20454 22448 20704 13963>,
			<14421 18514 20800 19318 19588>,
			<13184 14610 19080 22293 23322>,
			<25643 11388 14475 17228 22642>,
			<24060 25971 9950 13885 16629>,
			<23936 27140 27442 9156 10679>,
			<15615 24814 27349 27452 9156>,
			<10679 15615 24814 27349 27452>,
			<9156 10679 15615 24814 27349>,
			<27452>;
	};

	qcom,pc-temp-y6-lut {
		qcom,lut-col-legend = <(-10) 0 10 25 40 50>;
		qcom,lut-row-legend = <10000 9800 9600 9400 9200>,
			<9000 8800 8600 8400 8200>,
			<8000 7800 7600 7400 7200>,
			<7000 6800 6600 6400 6200>,
			<6000 5800 5600 5400 5200>,
			<5000 4800 4600 4400 4200>,
			<4000 3800 3600 3400 3200>,
			<3000 2800 2600 2400 2200>,
			<2000 1800 1600 1400 1200>,
			<1000 900 800 700 600>,
			<500 400 300 200 100>,
			<0>;

		qcom,lut-data = <5503 5190 5053 4968 4935>,
			<4926 5514 5207 5062 4967>,
			<4934 4926 5524 5220 5068>,
			<4967 4934 4926 5531 5230>,
			<5072 4966 4934 4926 5536>,
			<5236 5073 4965 4933 4926>,
			<5538 5238 5073 4965 4933>,
			<4926 5536 5235 5071 4965>,
			<4934 4926 5533 5228 5067>,
			<4964 4934 4927 5528 5224>,
			<5064 4964 4935 4927 5521>,
			<5220 5062 4965 4935 4928>,
			<5515 5218 5061 4966 4936>,
			<4928 5513 5218 5061 4967>,
			<4937 4929 5512 5218 5062>,
			<4969 4938 4930 5516 5219>,
			<5062 4971 4940 4931 5547>,
			<5223 5064 4973 4942 4932>,
			<5568 5229 5067 4976 4944>,
			<4934 5554 5241 5074 4979>,
			<4946 4935 5524 5255 5085>,
			<4983 4948 4937 5502 5254>,
			<5091 4989 4951 4940 5481>,
			<5231 5095 4999 4957 4944>,
			<5464 5207 5097 5005 4960>,
			<4946 5451 5190 5080 4997>,
			<4957 4944 5441 5175 5051>,
			<4981 4951 4939 5432 5166>,
			<5039 4971 4945 4934 5422>,
			<5160 5032 4963 4937 4929>,
			<5418 5156 5029 4958 4933>,
			<4926 5421 5154 5028 4959>,
			<4933 4926 5430 5153 5028>,
			<4959 4934 4927 5440 5152>,
			<5028 4961 4934 4928 5455>,
			<5148 5029 4963 4936 4929>,
			<5473 5146 5030 4966 4938>,
			<4930 5492 5149 5032 4968>,
			<4940 4932 5514 5155 5034>,
			<4970 4942 4934 5538 5164>,
			<5035 4972 4944 4935 5564>,
			<5180 5035 4974 4946 4937>,
			<5592 5198 5035 4975 4947>,
			<4937 5625 5218 5039 4973>,
			<4944 4934 5661 5240 5045>,
			<4968 4939 4930 5698 5263>,
			<5050 4965 4936 4929 5736>,
			<5288 5054 4963 4934 4929>,
			<5776 5312 5060 4962 4934>,
			<4929 5817 5332 5068 4963>,
			<4934 4929 5861 5352 5079>,
			<4966 4934 4929 5915 5379>,
			<5093 4967 4932 4926 5991>,
			<5419 5110 4970 4932 4925>,
			<6074 5460 5112 4972 4935>,
			<4928 6139 5493 5122 4976>,
			<4937 4931 6230 5543 5143>,
			<4982 4941 4938 6362 5606>,
			<5165 4989 4952 4951 6568>,
			<5683 5194 4996 4953 4937>,
			<7089 5782 5213 4985 4938>,
			<4931 8515 5979 5260 4991>,
			<4940 4933 11813 6525 5348>,
			<5004 4946 4940 20701 8475>,
			<5516 5024 4960 4958 20701>,
			<8475 5516 5024 4960 4958>,
			<20701 8475 5516 5024 4960>,
			<4958>;
	};
};
